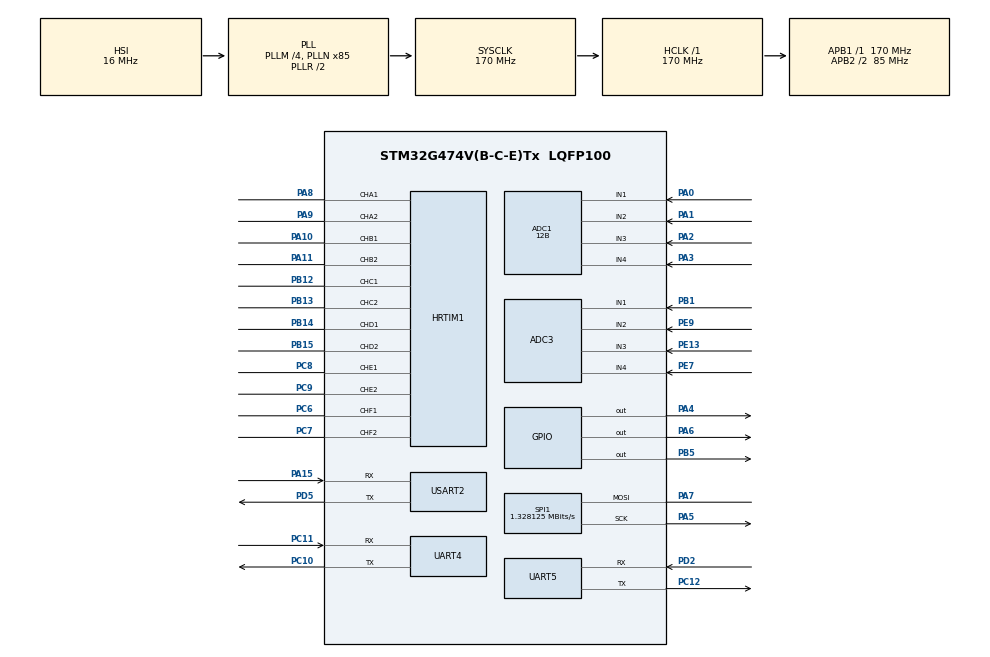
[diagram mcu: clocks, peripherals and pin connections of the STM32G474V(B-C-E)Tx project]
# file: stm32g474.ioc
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ADC1.Channel-1\#ChannelRegularConversion=ADC_CHANNEL_1
ADC1.Channel-2\#ChannelRegularConversion=ADC_CHANNEL_2
ADC1.Channel-3\#ChannelRegularConversion=ADC_CHANNEL_3
ADC1.Channel-4\#ChannelRegularConversion=ADC_CHANNEL_4
ADC1.ClockPrescaler=ADC_CLOCK_SYNC_PCLK_DIV4
ADC1.ContinuousConvMode=ENABLE
ADC1.DMAContinuousRequests=ENABLE
ADC1.ExternalTrigConv=ADC_EXTERNALTRIG_T3_TRGO
ADC1.NbrOfConversion=4
ADC1.NbrOfConversionFlag=1
ADC1.OffsetNumber-1\#ChannelRegularConversion=ADC_OFFSET_NONE
ADC1.OffsetNumber-2\#ChannelRegularConversion=ADC_OFFSET_NONE
ADC1.OffsetNumber-3\#ChannelRegularConversion=ADC_OFFSET_NONE
ADC1.OffsetNumber-4\#ChannelRegularConversion=ADC_OFFSET_NONE
ADC1.Overrun=ADC_OVR_DATA_PRESERVED
ADC1.OversamplingMode=ENABLE
ADC1.Rank-1\#ChannelRegularConversion=1
ADC1.Rank-2\#ChannelRegularConversion=2
ADC1.Rank-3\#ChannelRegularConversion=3
ADC1.Rank-4\#ChannelRegularConversion=4
ADC1.Ratio=ADC_OVERSAMPLING_RATIO_64
ADC1.Resolution=ADC_RESOLUTION_12B
ADC1.RightBitShift=ADC_RIGHTBITSHIFT_2
ADC1.SamplingTime-1\#ChannelRegularConversion=ADC_SAMPLETIME_2CYCLES_5
ADC1.SamplingTime-2\#ChannelRegularConversion=ADC_SAMPLETIME_2CYCLES_5
ADC1.SamplingTime-3\#ChannelRegularConversion=ADC_SAMPLETIME_2CYCLES_5
ADC1.SamplingTime-4\#ChannelRegularConversion=ADC_SAMPLETIME_2CYCLES_5
ADC1.master=1
ADC3.Channel-0\#ChannelRegularConversion=ADC_CHANNEL_1
ADC3.Channel-1\#ChannelRegularConversion=ADC_CHANNEL_2
ADC3.Channel-2\#ChannelRegularConversion=ADC_CHANNEL_3
ADC3.Channel-3\#ChannelRegularConversion=ADC_CHANNEL_4
ADC3.ContinuousConvMode=ENABLE
ADC3.DMAContinuousRequests=ENABLE
ADC3.ExternalTrigConv=ADC_EXTERNALTRIG_T4_TRGO
ADC3.ExternalTrigConvEdge=ADC_EXTERNALTRIGCONVEDGE_RISING
ADC3.NbrOfConversion=4
ADC3.NbrOfConversionFlag=1
ADC3.OffsetNumber-0\#ChannelRegularConversion=ADC_OFFSET_NONE
ADC3.OffsetNumber-1\#ChannelRegularConversion=ADC_OFFSET_NONE
ADC3.OffsetNumber-2\#ChannelRegularConversion=ADC_OFFSET_NONE
ADC3.OffsetNumber-3\#ChannelRegularConversion=ADC_OFFSET_NONE
ADC3.OversamplingMode=ENABLE
ADC3.Rank-0\#ChannelRegularConversion=1
ADC3.Rank-1\#ChannelRegularConversion=2
ADC3.Rank-2\#ChannelRegularConversion=3
ADC3.Rank-3\#ChannelRegularConversion=4
ADC3.Ratio=ADC_OVERSAMPLING_RATIO_64
ADC3.RightBitShift=ADC_RIGHTBITSHIFT_2
ADC3.SamplingTime-0\#ChannelRegularConversion=ADC_SAMPLETIME_2CYCLES_5
ADC3.SamplingTime-1\#ChannelRegularConversion=ADC_SAMPLETIME_2CYCLES_5
ADC3.SamplingTime-2\#ChannelRegularConversion=ADC_SAMPLETIME_2CYCLES_5
ADC3.SamplingTime-3\#ChannelRegularConversion=ADC_SAMPLETIME_2CYCLES_5
ADC3.master=1
Dma.ADC1.0.Direction=DMA_PERIPH_TO_MEMORY
Dma.ADC1.0.EventEnable=DISABLE
Dma.ADC1.0.Instance=DMA1_Channel1
Dma.ADC1.0.MemDataAlignment=DMA_MDATAALIGN_HALFWORD
Dma.ADC1.0.MemInc=DMA_MINC_ENABLE
Dma.ADC1.0.Mode=DMA_CIRCULAR
Dma.ADC1.0.PeriphDataAlignment=DMA_PDATAALIGN_HALFWORD
Dma.ADC1.0.PeriphInc=DMA_PINC_DISABLE
Dma.ADC1.0.Polarity=HAL_DMAMUX_REQ_GEN_RISING
Dma.ADC1.0.Priority=DMA_PRIORITY_MEDIUM
Dma.ADC1.0.RequestNumber=1
Dma.ADC1.0.SignalID=NONE
Dma.ADC1.0.SyncEnable=DISABLE
Dma.ADC1.0.SyncPolarity=HAL_DMAMUX_SYNC_NO_EVENT
Dma.ADC1.0.SyncRequestNumber=1
Dma.ADC1.0.SyncSignalID=NONE
Dma.ADC3.1.Direction=DMA_PERIPH_TO_MEMORY
Dma.ADC3.1.EventEnable=DISABLE
Dma.ADC3.1.Instance=DMA1_Channel2
Dma.ADC3.1.MemDataAlignment=DMA_MDATAALIGN_HALFWORD
Dma.ADC3.1.MemInc=DMA_MINC_ENABLE
Dma.ADC3.1.Mode=DMA_CIRCULAR
Dma.ADC3.1.PeriphDataAlignment=DMA_PDATAALIGN_HALFWORD
Dma.ADC3.1.PeriphInc=DMA_PINC_DISABLE
Dma.ADC3.1.Polarity=HAL_DMAMUX_REQ_GEN_RISING
Dma.ADC3.1.Priority=DMA_PRIORITY_MEDIUM
Dma.ADC3.1.RequestNumber=1
Dma.ADC3.1.SignalID=NONE
Dma.ADC3.1.SyncEnable=DISABLE
Dma.ADC3.1.SyncPolarity=HAL_DMAMUX_SYNC_NO_EVENT
Dma.ADC3.1.SyncRequestNumber=1
Dma.ADC3.1.SyncSignalID=NONE
Dma.Request0=ADC1
Dma.Request1=ADC3
Dma.Request2=SPI1_TX
Dma.SPI1_TX.2.Direction=DMA_MEMORY_TO_PERIPH
Dma.SPI1_TX.2.EventEnable=DISABLE
Dma.SPI1_TX.2.Instance=DMA2_Channel1
Dma.SPI1_TX.2.MemDataAlignment=DMA_MDATAALIGN_BYTE
Dma.SPI1_TX.2.MemInc=DMA_MINC_ENABLE
Dma.SPI1_TX.2.Mode=DMA_NORMAL
Dma.SPI1_TX.2.PeriphDataAlignment=DMA_PDATAALIGN_BYTE
Dma.SPI1_TX.2.PeriphInc=DMA_PINC_DISABLE
Dma.SPI1_TX.2.Polarity=HAL_DMAMUX_REQ_GEN_RISING
Dma.SPI1_TX.2.Priority=DMA_PRIORITY_MEDIUM
Dma.SPI1_TX.2.RequestNumber=1
Dma.SPI1_TX.2.SignalID=NONE
Dma.SPI1_TX.2.SyncEnable=DISABLE
Dma.SPI1_TX.2.SyncPolarity=HAL_DMAMUX_SYNC_NO_EVENT
Dma.SPI1_TX.2.SyncRequestNumber=1
Dma.SPI1_TX.2.SyncSignalID=NONE
HRTIM1.CompareUnit1-Output_TA1TA2=HRTIM_COMPAREUNIT_1
HRTIM1.CompareUnit1-Output_TB1TB2=HRTIM_COMPAREUNIT_1
HRTIM1.CompareUnit1-Output_TC1TC2=HRTIM_COMPAREUNIT_1
HRTIM1.CompareUnit1-Output_TD1TD2=HRTIM_COMPAREUNIT_1
HRTIM1.CompareUnit1-Output_TE1TE2=HRTIM_COMPAREUNIT_1
HRTIM1.CompareUnit1-Output_TF1TF2=HRTIM_COMPAREUNIT_1
HRTIM1.CompareValue1-Output_TA1TA2=160
HRTIM1.CompareValue1-Output_TB1TB2=1400
HRTIM1.CompareValue1-Output_TC1TC2=10
HRTIM1.CompareValue1-Output_TD1TD2=100
HRTIM1.CompareValue1-Output_TE1TE2=100
HRTIM1.CompareValue1-Output_TF1TF2=120
HRTIM1.Configuration_TF=Waveform
HRTIM1.DeadTimeInsertion-Output_TA1TA2=HRTIM_TIMDEADTIMEINSERTION_ENABLED
HRTIM1.DeadTimeInsertion-Output_TB1TB2=HRTIM_TIMDEADTIMEINSERTION_ENABLED
HRTIM1.DeadTimeInsertion-Output_TC1TC2=HRTIM_TIMDEADTIMEINSERTION_ENABLED
HRTIM1.DeadTimeInsertion-Output_TD1TD2=HRTIM_TIMDEADTIMEINSERTION_ENABLED
HRTIM1.DeadTimeInsertion-Output_TE1TE2=HRTIM_TIMDEADTIMEINSERTION_ENABLED
HRTIM1.DeadTimeInsertion-Output_TF1TF2=HRTIM_TIMDEADTIMEINSERTION_ENABLED
HRTIM1.FallingValue-Output_TA1TA2=16
HRTIM1.FallingValue-Output_TB1TB2=16
HRTIM1.FallingValue-Output_TC1TC2=16
HRTIM1.FallingValue-Output_TD1TD2=16
HRTIM1.FallingValue-Output_TE1TE2=16
HRTIM1.FallingValue-Output_TF1TF2=16
HRTIM1.NumberFaultEnable-Output_TB1TB2=0
HRTIM1.NumberResetSource1-Output_TA1TA2=1
HRTIM1.NumberResetSource1-Output_TB1TB2=1
HRTIM1.NumberResetSource1-Output_TC1TC2=1
HRTIM1.NumberResetSource1-Output_TD1TD2=1
HRTIM1.NumberResetSource1-Output_TE1TE2=1
HRTIM1.NumberResetSource1-Output_TF1TF2=1
HRTIM1.NumberResetTrigger-Output_TA1TA2=1
HRTIM1.NumberResetTrigger-Output_TB1TB2=1
HRTIM1.NumberResetTrigger-Output_TC1TC2=1
HRTIM1.NumberResetTrigger-Output_TD1TD2=1
HRTIM1.NumberResetTrigger-Output_TE1TE2=1
HRTIM1.NumberResetTrigger-Output_TF1TF2=1
HRTIM1.NumberSetSource1-Output_TA1TA2=1
HRTIM1.NumberSetSource1-Output_TB1TB2=1
HRTIM1.NumberSetSource1-Output_TC1TC2=1
HRTIM1.NumberSetSource1-Output_TD1TD2=1
HRTIM1.NumberSetSource1-Output_TE1TE2=1
HRTIM1.NumberSetSource1-Output_TF1TF2=1
HRTIM1.NumberUpdateTrigger-Output_TA1TA2=0
HRTIM1.NumberUpdateTrigger-Output_TB1TB2=0
HRTIM1.NumberUpdateTrigger-Output_TC1TC2=0
HRTIM1.Periode_MASTER=21760
HRTIM1.Periode_TA=21760
HRTIM1.Periode_TB=21760
HRTIM1.Periode_TC=21760
HRTIM1.Periode_TD=21760
HRTIM1.Periode_TE=21760
HRTIM1.Periode_TF=21760
HRTIM1.PreloadEnable-MasterTimer=HRTIM_PRELOAD_ENABLED
HRTIM1.PreloadEnable-Output_TA1TA2=HRTIM_PRELOAD_ENABLED
HRTIM1.PreloadEnable-Output_TB1TB2=HRTIM_PRELOAD_ENABLED
HRTIM1.PreloadEnable-Output_TC1TC2=HRTIM_PRELOAD_ENABLED
HRTIM1.PreloadEnable-Output_TD1TD2=HRTIM_PRELOAD_ENABLED
HRTIM1.PreloadEnable-Output_TE1TE2=HRTIM_PRELOAD_ENABLED
HRTIM1.PreloadEnable-Output_TF1TF2=HRTIM_PRELOAD_ENABLED
HRTIM1.RepetitionCounter-MasterTimer=0x01
HRTIM1.RepetitionCounter-Output_TA1TA2=1
HRTIM1.RepetitionUpdate-MasterTimer=HRTIM_UPDATEONREPETITION_ENABLED
HRTIM1.RepetitionUpdate-Output_TA1TA2=HRTIM_UPDATEONREPETITION_ENABLED
HRTIM1.RepetitionUpdate-Output_TB1TB2=HRTIM_UPDATEONREPETITION_ENABLED
HRTIM1.RepetitionUpdate-Output_TC1TC2=HRTIM_UPDATEONREPETITION_ENABLED
HRTIM1.RepetitionUpdate-Output_TD1TD2=HRTIM_UPDATEONREPETITION_ENABLED
HRTIM1.RepetitionUpdate-Output_TE1TE2=HRTIM_UPDATEONREPETITION_ENABLED
HRTIM1.RepetitionUpdate-Output_TF1TF2=HRTIM_UPDATEONREPETITION_ENABLED
HRTIM1.ResetOutput1_Source1-Output_TA1TA2=HRTIM_OUTPUTRESET_TIMCMP1
HRTIM1.ResetOutput1_Source1-Output_TB1TB2=HRTIM_OUTPUTRESET_TIMCMP1
HRTIM1.ResetOutput1_Source1-Output_TC1TC2=HRTIM_OUTPUTRESET_TIMCMP1
HRTIM1.ResetOutput1_Source1-Output_TD1TD2=HRTIM_OUTPUTRESET_TIMCMP1
HRTIM1.ResetOutput1_Source1-Output_TE1TE2=HRTIM_OUTPUTRESET_TIMCMP1
HRTIM1.ResetOutput1_Source1-Output_TF1TF2=HRTIM_OUTPUTRESET_TIMCMP1
HRTIM1.ResetTrigger1-Output_TA1TA2=HRTIM_TIMRESETTRIGGER_MASTER_PER
HRTIM1.ResetTrigger1-Output_TB1TB2=HRTIM_TIMRESETTRIGGER_MASTER_PER
HRTIM1.ResetTrigger1-Output_TC1TC2=HRTIM_TIMRESETTRIGGER_MASTER_PER
HRTIM1.ResetTrigger1-Output_TD1TD2=HRTIM_TIMRESETTRIGGER_MASTER_PER
HRTIM1.ResetTrigger1-Output_TE1TE2=HRTIM_TIMRESETTRIGGER_MASTER_PER
HRTIM1.ResetTrigger1-Output_TF1TF2=HRTIM_TIMRESETTRIGGER_MASTER_PER
HRTIM1.ResetUpdate-Output_TA1TA2=HRTIM_TIMUPDATEONRESET_DISABLED
HRTIM1.RisingValue-Output_TA1TA2=16
HRTIM1.RisingValue-Output_TB1TB2=16
HRTIM1.RisingValue-Output_TC1TC2=16
HRTIM1.RisingValue-Output_TD1TD2=16
HRTIM1.RisingValue-Output_TE1TE2=16
HRTIM1.RisingValue-Output_TF1TF2=16
HRTIM1.SetOutput1_Source1-Output_TA1TA2=HRTIM_OUTPUTSET_TIMPER
HRTIM1.SetOutput1_Source1-Output_TB1TB2=HRTIM_OUTPUTSET_TIMPER
HRTIM1.SetOutput1_Source1-Output_TC1TC2=HRTIM_OUTPUTSET_TIMPER
HRTIM1.SetOutput1_Source1-Output_TD1TD2=HRTIM_OUTPUTSET_TIMPER
HRTIM1.SetOutput1_Source1-Output_TE1TE2=HRTIM_OUTPUTSET_TIMPER
HRTIM1.SetOutput1_Source1-Output_TF1TF2=HRTIM_OUTPUTSET_TIMPER
HRTIM1.SyncOptions=HRTIM_SYNCOPTION_NONE
Mcu.Family=STM32G4
Mcu.Name=STM32G474V(B-C-E)Tx
Mcu.Package=LQFP100
NVIC.DMA1_Channel1_IRQn=true\:0\:0\:false\:false\:true\:false\:true\:true
NVIC.DMA1_Channel2_IRQn=true\:0\:0\:false\:false\:true\:false\:true\:true
NVIC.DMA2_Channel1_IRQn=true\:0\:0\:false\:false\:true\:false\:true\:true
NVIC.PriorityGroup=NVIC_PRIORITYGROUP_4
NVIC.TIM1_TRG_COM_TIM17_IRQn=true\:0\:0\:false\:false\:true\:true\:true\:true
NVIC.TIM1_UP_TIM16_IRQn=true\:0\:0\:false\:false\:true\:true\:true\:true
NVIC.TIM6_DAC_IRQn=true\:0\:0\:false\:false\:true\:true\:true\:true
NVIC.TIM7_DAC_IRQn=true\:0\:0\:false\:false\:true\:true\:true\:true
NVIC.UART4_IRQn=true\:0\:0\:false\:false\:true\:true\:true\:true
NVIC.UART5_IRQn=true\:0\:0\:false\:false\:true\:true\:true\:true
NVIC.USART2_IRQn=true\:0\:0\:false\:false\:true\:true\:true\:true
PA0.Mode=IN1-Single-Ended
PA0.Signal=ADC1_IN1
PA1.Mode=IN2-Single-Ended
PA1.Signal=ADC1_IN2
PA10.Mode=Output_TB1TB2
PA10.Signal=HRTIM1_CHB1
PA11.Mode=Output_TB1TB2
PA11.Signal=HRTIM1_CHB2
PA13.Mode=Serial_Wire
PA13.Signal=SYS_JTMS-SWDIO
PA14.Mode=Serial_Wire
PA14.Signal=SYS_JTCK-SWCLK
PA15.Mode=Asynchronous
PA15.Signal=USART2_RX
PA2.Mode=IN3-Single-Ended
PA2.Signal=ADC1_IN3
PA3.Mode=IN4-Single-Ended
PA3.Signal=ADC1_IN4
PA4.GPIO_Speed=GPIO_SPEED_FREQ_LOW
PA4.PinState=GPIO_PIN_RESET
PA4.Signal=GPIO_Output
PA5.Mode=Simplex_Bidirectional_Master
PA5.Signal=SPI1_SCK
PA6.GPIO_Speed=GPIO_SPEED_FREQ_LOW
PA6.PinState=GPIO_PIN_RESET
PA6.Signal=GPIO_Output
PA7.Mode=Simplex_Bidirectional_Master
PA7.Signal=SPI1_MOSI
PA8.Mode=Output_TA1TA2
PA8.Signal=HRTIM1_CHA1
PA9.Mode=Output_TA1TA2
PA9.Signal=HRTIM1_CHA2
PB1.Mode=IN1-Single-Ended
PB1.Signal=ADC3_IN1
PB12.Mode=Output_TC1TC2
PB12.Signal=HRTIM1_CHC1
PB13.Mode=Output_TC1TC2
PB13.Signal=HRTIM1_CHC2
PB14.Mode=Output_TD1TD2
PB14.Signal=HRTIM1_CHD1
PB15.Mode=Output_TD1TD2
PB15.Signal=HRTIM1_CHD2
PB5.GPIO_Speed=GPIO_SPEED_FREQ_LOW
PB5.PinState=GPIO_PIN_RESET
PB5.Signal=GPIO_Output
PC10.Mode=Asynchronous
PC10.Signal=UART4_TX
PC11.Mode=Asynchronous
PC11.Signal=UART4_RX
PC12.Mode=Asynchronous
PC12.Signal=UART5_TX
PC6.Mode=Output_TF1TF2
PC6.Signal=HRTIM1_CHF1
PC7.Mode=Output_TF1TF2
PC7.Signal=HRTIM1_CHF2
PC8.Mode=Output_TE1TE2
PC8.Signal=HRTIM1_CHE1
PC9.Mode=Output_TE1TE2
PC9.Signal=HRTIM1_CHE2
PD2.Mode=Asynchronous
PD2.Signal=UART5_RX
PD5.Mode=Asynchronous
PD5.Signal=USART2_TX
PE13.Mode=IN3-Single-Ended
PE13.Signal=ADC3_IN3
PE7.Mode=IN4-Single-Ended
PE7.Signal=ADC3_IN4
PE9.Mode=IN2-Single-Ended
PE9.Signal=ADC3_IN2
PF0-OSC_IN.Mode=HSE-External-Oscillator
PF0-OSC_IN.Signal=RCC_OSC_IN
PF1-OSC_OUT.Mode=HSE-External-Oscillator
PF1-OSC_OUT.Signal=RCC_OSC_OUT
ProjectManager.HeapSize=0x200
ProjectManager.StackSize=0x400
ProjectManager.TargetToolchain=MDK-ARM V5.32
RCC.ADC12Freq_Value=170000000
RCC.ADC345Freq_Value=170000000
RCC.AHBFreq_Value=170000000
RCC.APB1Freq_Value=170000000
RCC.APB1TimFreq_Value=170000000
RCC.APB2CLKDivider=RCC_HCLK_DIV2
RCC.APB2Freq_Value=85000000
RCC.APB2TimFreq_Value=170000000
RCC.CortexFreq_Value=170000000
RCC.EXTERNAL_CLOCK_VALUE=12288000
RCC.HCLKFreq_Value=170000000
RCC.HSE_VALUE=8000000
RCC.HSI48_VALUE=48000000
RCC.HSI_VALUE=16000000
RCC.LSE_VALUE=32768
RCC.PLLM=RCC_PLLM_DIV4
RCC.PLLN=85
RCC.SYSCLKFreq_VALUE=170000000
RCC.SYSCLKSource=RCC_SYSCLKSOURCE_PLLCLK
RCC.USBFreq_Value=170000000
RCC.VCOOutputFreq_Value=340000000
SPI1.BaudRatePrescaler=SPI_BAUDRATEPRESCALER_64
SPI1.CLKPhase=SPI_PHASE_1EDGE
SPI1.CLKPolarity=SPI_POLARITY_LOW
SPI1.CalculateBaudRate=1.328125 MBits/s
SPI1.DataSize=SPI_DATASIZE_8BIT
SPI1.Direction=SPI_DIRECTION_1LINE
SPI1.Mode=SPI_MODE_MASTER
SPI1.VirtualType=VM_MASTER
TIM16.AutoReloadPreload=TIM_AUTORELOAD_PRELOAD_ENABLE
TIM16.PeriodNoDither=20000-1
TIM16.Prescaler=170-1
TIM17.AutoReloadPreload=TIM_AUTORELOAD_PRELOAD_ENABLE
TIM17.PeriodNoDither=20000-1
TIM17.Prescaler=170-1
TIM3.AutoReloadPreload=TIM_AUTORELOAD_PRELOAD_ENABLE
TIM3.PeriodNoDither=170-1
TIM3.Prescaler=0
TIM3.TIM_MasterOutputTrigger=TIM_TRGO_UPDATE
TIM4.AutoReloadPreload=TIM_AUTORELOAD_PRELOAD_ENABLE
TIM4.PeriodNoDither=170-1
TIM4.TIM_MasterOutputTrigger=TIM_TRGO_UPDATE
TIM6.AutoReloadPreload=TIM_AUTORELOAD_PRELOAD_ENABLE
TIM6.PeriodNoDither=100-1
TIM6.Prescaler=170-1
TIM7.AutoReloadPreload=TIM_AUTORELOAD_PRELOAD_ENABLE
TIM7.PeriodNoDither=100-1
TIM7.Prescaler=170-1
USART2.VirtualMode-Asynchronous=VM_ASYNC
VP_HRTIM1_VS_hrtimMasterTimerNoOutput.Mode=MasterTimer
VP_SYS_VS_DBSignals.Mode=DisableDeadBatterySignals
VP_TIM16_VS_ClockSourceINT.Mode=Enable_Timer
VP_TIM17_VS_ClockSourceINT.Mode=Enable_Timer
VP_TIM3_VS_ClockSourceINT.Mode=Internal
VP_TIM4_VS_ClockSourceINT.Mode=Internal
VP_TIM6_VS_ClockSourceINT.Mode=Enable_Timer
VP_TIM7_VS_ClockSourceINT.Mode=Enable_Timer
board=custom

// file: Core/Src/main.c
/* USER CODE BEGIN Header */
/**
  ******************************************************************************
  * @file           : main.c
  * @brief          : Main program body
  ******************************************************************************
  * @attention
  *
  * Copyright (c) 2025 STMicroelectronics.
  * All rights reserved.
  *
  * This software is licensed under terms that can be found in the LICENSE file
  * in the root directory of this software component.
  * If no LICENSE file comes with this software, it is provided AS-IS.
  *
  ******************************************************************************
  */
/* USER CODE END Header */
#include "main.h"
#include "adc.h"
#include "dma.h"
#include "hrtim.h"
#include "spi.h"
#include "tim.h"
#include "usart.h"
#include "gpio.h"

/* USER CODE BEGIN Includes */
#include "task_impl.h"
/* USER CODE END Includes */

void SystemClock_Config(void);

int main(void)
{

  /* MCU Configuration--------------------------------------------------------*/

  /* Reset of all peripherals, Initializes the Flash interface and the Systick. */
  HAL_Init();

  /* Configure the system clock */
  SystemClock_Config();

  /* Initialize all configured peripherals */
  MX_GPIO_Init();
  MX_DMA_Init();
  MX_ADC1_Init();
  MX_ADC3_Init();
  MX_HRTIM1_Init();
  MX_USART2_UART_Init();
  MX_TIM6_Init();
  MX_TIM7_Init();
  MX_TIM16_Init();
  MX_TIM17_Init();
  MX_SPI1_Init();
  MX_TIM3_Init();
  MX_TIM4_Init();
  MX_UART4_Init();
  MX_UART5_Init();
  /* USER CODE BEGIN 2 */
	task_start();
  /* USER CODE END 2 */

  /* Infinite loop */
  while (1)
  {

    /* USER CODE BEGIN 3 */
		    OLED_Refresh_Gram();
		__WFE();
  }
  /* USER CODE END 3 */
}

void SystemClock_Config(void)
{
  RCC_OscInitTypeDef RCC_OscInitStruct = {0};
  RCC_ClkInitTypeDef RCC_ClkInitStruct = {0};

  /** Configure the main internal regulator output voltage
  */
  HAL_PWREx_ControlVoltageScaling(PWR_REGULATOR_VOLTAGE_SCALE1_BOOST);

  /** Initializes the RCC Oscillators according to the specified parameters
  * in the RCC_OscInitTypeDef structure.
  */
  RCC_OscInitStruct.OscillatorType = RCC_OSCILLATORTYPE_HSI;
  RCC_OscInitStruct.HSIState = RCC_HSI_ON;
  RCC_OscInitStruct.HSICalibrationValue = RCC_HSICALIBRATION_DEFAULT;
  RCC_OscInitStruct.PLL.PLLState = RCC_PLL_ON;
  RCC_OscInitStruct.PLL.PLLSource = RCC_PLLSOURCE_HSI;
  RCC_OscInitStruct.PLL.PLLM = RCC_PLLM_DIV4;
  RCC_OscInitStruct.PLL.PLLN = 85;
  RCC_OscInitStruct.PLL.PLLP = RCC_PLLP_DIV2;
  RCC_OscInitStruct.PLL.PLLQ = RCC_PLLQ_DIV2;
  RCC_OscInitStruct.PLL.PLLR = RCC_PLLR_DIV2;
  if (HAL_RCC_OscConfig(&RCC_OscInitStruct) != HAL_OK)
  {
    Error_Handler();
  }

  /** Initializes the CPU, AHB and APB buses clocks
  */
  RCC_ClkInitStruct.ClockType = RCC_CLOCKTYPE_HCLK|RCC_CLOCKTYPE_SYSCLK
                              |RCC_CLOCKTYPE_PCLK1|RCC_CLOCKTYPE_PCLK2;
  RCC_ClkInitStruct.SYSCLKSource = RCC_SYSCLKSOURCE_PLLCLK;
  RCC_ClkInitStruct.AHBCLKDivider = RCC_SYSCLK_DIV1;
  RCC_ClkInitStruct.APB1CLKDivider = RCC_HCLK_DIV1;
  RCC_ClkInitStruct.APB2CLKDivider = RCC_HCLK_DIV2;

  if (HAL_RCC_ClockConfig(&RCC_ClkInitStruct, FLASH_LATENCY_4) != HAL_OK)
  {
    Error_Handler();
  }
}

void Error_Handler(void)
{
  __disable_irq();
  while (1)
  {
  }
}
